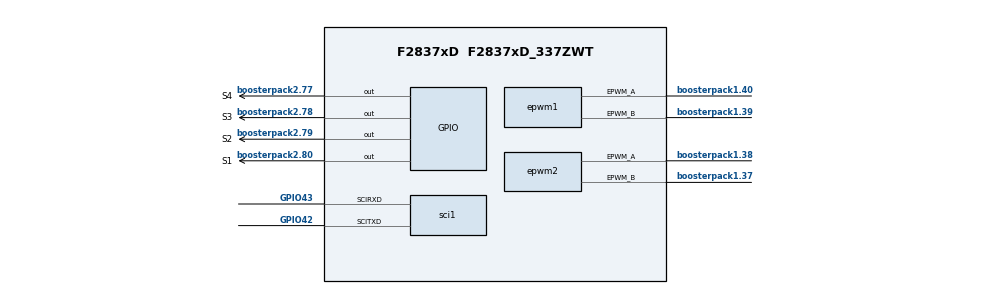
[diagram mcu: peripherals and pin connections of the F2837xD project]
/**
 * @cliArgs --board "/boards/LAUNCHXL_F28379D" --device "F2837xD" --part "F2837xD_337ZWT" --package "F2837xD_337ZWT" --context "CPU1" --product "C2000WARE@26.00.00.00"
 * @versions {"tool":"1.27.0+4565"}
 */

/**
 * Import the modules used in this configuration.
 */
const adc              = scripting.addModule("/driverlib/adc.js", {}, false);
const adc1             = adc.addInstance();
const cla              = scripting.addModule("/driverlib/cla.js", {}, false);
const cla1             = cla.addInstance();
const cputimer         = scripting.addModule("/driverlib/cputimer.js", {}, false);
const cputimer1        = cputimer.addInstance();
const cputimer2        = cputimer.addInstance();
const dac              = scripting.addModule("/driverlib/dac.js", {}, false);
const dac1             = dac.addInstance();
const dac2             = dac.addInstance();
const epwm             = scripting.addModule("/driverlib/epwm.js", {}, false);
const epwm1            = epwm.addInstance();
const epwm2            = epwm.addInstance();
const gpio             = scripting.addModule("/driverlib/gpio.js", {}, false);
const gpio1            = gpio.addInstance();
const gpio2            = gpio.addInstance();
const gpio3            = gpio.addInstance();
const gpio4            = gpio.addInstance();
const inputxbar_input  = scripting.addModule("/driverlib/inputxbar_input.js", {}, false);
const inputxbar_input1 = inputxbar_input.addInstance();
const inputxbar_input2 = inputxbar_input.addInstance();
const inputxbar_input3 = inputxbar_input.addInstance();
const inputxbar_input4 = inputxbar_input.addInstance();
const memcfg           = scripting.addModule("/driverlib/memcfg.js");
const sci              = scripting.addModule("/driverlib/sci.js", {}, false);
const sci1             = sci.addInstance();

/**
 * Write custom configuration values to the imported modules.
 */
adc1.adcClockPrescaler              = "ADC_CLK_DIV_4_0";
adc1.$name                          = "ADC0";
adc1.soc0SampleWindow               = 15;
adc1.interruptPulseMode             = "ADC_PULSE_END_OF_CONV";
adc1.enabledInts                    = ["ADC_INT_NUMBER1"];
adc1.enableInterrupt1               = true;
adc1.enabledSOCs                    = ["ADC_SOC_NUMBER0","ADC_SOC_NUMBER1"];
adc1.interrupt1SOCSource            = "ADC_SOC_NUMBER1";
adc1.soc1Channel                    = "ADC_CH_ADCIN2";
adc1.soc1SampleWindow               = 15;
adc1.soc1Trigger                    = "ADC_TRIGGER_EPWM1_SOCA";
adc1.registerInterrupts             = ["1"];
adc1.soc0Trigger                    = "ADC_TRIGGER_EPWM1_SOCA";
adc1.useInterrupts                  = false;
adc1.enableInterrupt1ContinuousMode = true;

cla1.$name              = "myCLA0";
cla1.enable_CLA_TASK_2  = false;
cla1.enable_CLA_TASK_3  = false;
cla1.enable_CLA_TASK_4  = false;
cla1.enable_CLA_TASK_5  = false;
cla1.enable_CLA_TASK_6  = false;
cla1.enable_CLA_TASK_8  = false;
cla1.enable_CLA_TASK_7  = false;
cla1.cpuint_CLA_TASK_2  = false;
cla1.cpuint_CLA_TASK_3  = false;
cla1.cpuint_CLA_TASK_4  = false;
cla1.cpuint_CLA_TASK_5  = false;
cla1.cpuint_CLA_TASK_6  = false;
cla1.cpuint_CLA_TASK_7  = false;
cla1.cpuint_CLA_TASK_8  = false;
cla1.trigger_CLA_TASK_1 = "CLA_TRIGGER_ADCA1";
cla1.cpuint_CLA_TASK_1  = false;

cputimer1.$name                    = "myCPUTIMER0";
cputimer1.timerPeriod              = 499;
cputimer1.enableInterrupt          = true;
cputimer1.startTimer               = true;
cputimer1.registerInterrupts       = true;
cputimer1.timerInt.enableInterrupt = true;

cputimer2.$name        = "myCPUTIMER1";
cputimer2.timerPeriod  = 9999;
cputimer2.cputimerBase = "CPUTIMER1_BASE";
cputimer2.startTimer   = true;

dac1.$name            = "myDAC0";
dac1.enableOutput     = true;
dac1.referenceVoltage = "DAC_REF_ADC_VREFHI";

dac2.$name            = "myDAC1";
dac2.enableOutput     = true;
dac2.referenceVoltage = "DAC_REF_ADC_VREFHI";
dac2.dacBase          = "DACB_BASE";

epwm1.epwmTimebase_hsClockDiv                                    = "EPWM_HSCLOCK_DIVIDER_1";
epwm1.epwmTimebase_period                                        = 5000;
epwm1.epwmTimebase_counterMode                                   = "EPWM_COUNTER_MODE_UP_DOWN";
epwm1.epwmTimebase_counterModeAfterSync                          = "EPWM_COUNT_MODE_UP_AFTER_SYNC";
epwm1.epwmEventTrigger_EPWM_SOC_A_triggerEnable                  = true;
epwm1.epwmTimebase_syncOutPulseMode                              = "EPWM_SYNC_OUT_PULSE_ON_EPWMxSYNCIN";
epwm1.$name                                                      = "EPWM_S12";
epwm1.epwmActionQualifier_EPWM_AQ_OUTPUT_A_ON_TIMEBASE_UP_CMPA   = "EPWM_AQ_OUTPUT_LOW";
epwm1.epwmActionQualifier_EPWM_AQ_OUTPUT_A_ON_TIMEBASE_DOWN_CMPA = "EPWM_AQ_OUTPUT_HIGH";
epwm1.epwmActionQualifier_EPWM_AQ_OUTPUT_B_ON_TIMEBASE_UP_CMPA   = "EPWM_AQ_OUTPUT_HIGH";
epwm1.epwmActionQualifier_EPWM_AQ_OUTPUT_B_ON_TIMEBASE_DOWN_CMPA = "EPWM_AQ_OUTPUT_LOW";
epwm1.epwmEventTrigger_EPWM_SOC_A_triggerEventPrescalar          = "1";
epwm1.epwmEventTrigger_EPWM_SOC_A_triggerSource                  = "EPWM_SOC_TBCTR_PERIOD";
epwm1.epwm.$assign                                               = "EPWM1";
epwm1.epwm.epwm_aPin.$assign                                     = "boosterpack1.40";
epwm1.epwm.epwm_bPin.$assign                                     = "boosterpack1.39";
scripting.suppress("Connected to hardware,@@@.+?@@@ is connected to EPWM1 BP on the LaunchPad F28379D\\. Consider selecting it in \'use hardware\' above\\. @@@.+?@@@", epwm1.epwm, "epwm_aPin");
scripting.suppress("Connected to hardware,@@@.+?@@@ is connected to EPWM1 BP on the LaunchPad F28379D\\. Consider selecting it in \'use hardware\' above\\. @@@.+?@@@", epwm1.epwm, "epwm_bPin");

epwm2.epwmTimebase_hsClockDiv                                    = "EPWM_HSCLOCK_DIVIDER_1";
epwm2.epwmTimebase_period                                        = 5000;
epwm2.epwmTimebase_counterMode                                   = "EPWM_COUNTER_MODE_UP_DOWN";
epwm2.epwmTimebase_counterModeAfterSync                          = "EPWM_COUNT_MODE_UP_AFTER_SYNC";
epwm2.epwmTimebase_syncOutPulseMode                              = "EPWM_SYNC_OUT_PULSE_ON_EPWMxSYNCIN";
epwm2.$name                                                      = "EPWM_S34";
epwm2.epwmTimebase_periodLink                                    = "EPWM_LINK_WITH_EPWM_1";
epwm2.epwmActionQualifier_EPWM_AQ_OUTPUT_A_ON_TIMEBASE_UP_CMPA   = "EPWM_AQ_OUTPUT_LOW";
epwm2.epwmActionQualifier_EPWM_AQ_OUTPUT_A_ON_TIMEBASE_DOWN_CMPA = "EPWM_AQ_OUTPUT_HIGH";
epwm2.epwmActionQualifier_EPWM_AQ_OUTPUT_B_ON_TIMEBASE_UP_CMPA   = "EPWM_AQ_OUTPUT_HIGH";
epwm2.epwmActionQualifier_EPWM_AQ_OUTPUT_B_ON_TIMEBASE_DOWN_CMPA = "EPWM_AQ_OUTPUT_LOW";
epwm2.epwm.$assign                                               = "EPWM2";
epwm2.epwm.epwm_aPin.$assign                                     = "boosterpack1.38";
epwm2.epwm.epwm_bPin.$assign                                     = "boosterpack1.37";
scripting.suppress("Connected to hardware,@@@.+?@@@ is connected to EPWM2 BP on the LaunchPad F28379D\\. Consider selecting it in \'use hardware\' above\\. @@@.+?@@@", epwm2.epwm, "epwm_aPin");
scripting.suppress("Connected to hardware,@@@.+?@@@ is connected to EPWM2 BP on the LaunchPad F28379D\\. Consider selecting it in \'use hardware\' above\\. @@@.+?@@@", epwm2.epwm, "epwm_bPin");

gpio1.$name                     = "S1";
gpio1.useInterrupt              = true;
gpio1.gpioPin.$assign           = "boosterpack2.80";
gpio1.xint.intType              = "GPIO_INT_TYPE_BOTH_EDGES";
gpio1.xint.enableInt            = true;
gpio1.xint.registerInterrupts   = true;
gpio1.xint.xInt.enableInterrupt = true;
scripting.suppress("Connected to hardware,@@@.+?@@@ is connected to EPWM4 BP on the LaunchPad F28379D\\. Consider selecting it in \'use hardware\' above\\. @@@.+?@@@", gpio1, "gpioPin");

gpio2.$name                     = "S2";
gpio2.useInterrupt              = true;
gpio2.gpioPin.$assign           = "boosterpack2.79";
gpio2.xint.intType              = "GPIO_INT_TYPE_BOTH_EDGES";
gpio2.xint.enableInt            = true;
gpio2.xint.registerInterrupts   = true;
gpio2.xint.xintNum              = "GPIO_INT_XINT2";
gpio2.xint.xInt.enableInterrupt = true;
scripting.suppress("Connected to hardware,@@@.+?@@@ is connected to EPWM4 BP on the LaunchPad F28379D\\. Consider selecting it in \'use hardware\' above\\. @@@.+?@@@", gpio2, "gpioPin");

gpio3.$name                     = "S3";
gpio3.useInterrupt              = true;
gpio3.gpioPin.$assign           = "boosterpack2.78";
gpio3.xint.intType              = "GPIO_INT_TYPE_BOTH_EDGES";
gpio3.xint.enableInt            = true;
gpio3.xint.registerInterrupts   = true;
gpio3.xint.xintNum              = "GPIO_INT_XINT3";
gpio3.xint.xInt.enableInterrupt = true;
scripting.suppress("Connected to hardware,@@@.+?@@@ is connected to EPWM5 BP on the LaunchPad F28379D\\. Consider selecting it in \'use hardware\' above\\. @@@.+?@@@", gpio3, "gpioPin");

gpio4.$name                     = "S4";
gpio4.useInterrupt              = true;
gpio4.gpioPin.$assign           = "boosterpack2.77";
gpio4.xint.intType              = "GPIO_INT_TYPE_BOTH_EDGES";
gpio4.xint.enableInt            = true;
gpio4.xint.registerInterrupts   = true;
gpio4.xint.xintNum              = "GPIO_INT_XINT4";
gpio4.xint.xInt.enableInterrupt = true;
scripting.suppress("Connected to hardware,@@@.+?@@@ is connected to EPWM5 BP on the LaunchPad F28379D\\. Consider selecting it in \'use hardware\' above\\. @@@.+?@@@", gpio4, "gpioPin");

inputxbar_input1.$name         = "myINPUTXBARINPUT0";
gpio1.xint.inputxbar           = inputxbar_input1;
inputxbar_input1.inputxbarGpio = "GPIO6";

inputxbar_input2.$name         = "myINPUTXBARINPUT1";
gpio2.xint.inputxbar           = inputxbar_input2;
inputxbar_input2.inputxbarGpio = "GPIO7";

inputxbar_input3.$name         = "myINPUTXBARINPUT2";
gpio3.xint.inputxbar           = inputxbar_input3;
inputxbar_input3.inputxbarGpio = "GPIO8";

inputxbar_input4.$name         = "myINPUTXBARINPUT3";
gpio4.xint.inputxbar           = inputxbar_input4;
inputxbar_input4.inputxbarGpio = "GPIO9";

memcfg.config_MEMCFG_SECT_LS1 = "CLA_data";
memcfg.config_MEMCFG_SECT_LS4 = "CLA_prog";
memcfg.config_MEMCFG_SECT_LS5 = "CLA_prog";

sci1.$name                      = "SCI0";
sci1.selectRegisteredInterrupts = ["registerRxInt"];
sci1.enabledFIFOInterrupts      = ["SCI_INT_RXFF"];
sci1.rxFifo                     = "SCI_FIFO_RX4";
sci1.sci.scirxdPin.$assign      = "GPIO43";
sci1.sci.scitxdPin.$assign      = "GPIO42";
sci1.rxQual.$name               = "myGPIOQUAL0";
sci1.txQual.$name               = "myGPIOQUAL1";
sci1.sciRXInt.enableInterrupt   = true;

/**
 * Pinmux solution for unlocked pins/peripherals. This ensures that minor changes to the automatic solver in a future
 * version of the tool will not impact the pinmux you originally saw.  These lines can be completely deleted in order to
 * re-solve from scratch.
 */
sci1.sci.$suggestSolution = "SCIA";
